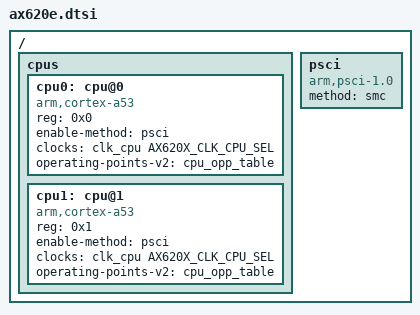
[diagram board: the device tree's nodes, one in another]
// SPDX-License-Identifier: GPL-2.0-or-later
/* AX630C AArch64 firmware uses PSCI. */
#include "../../../../arm/boot/dts/axera/ax620e-common.dtsi"

/ {
	cpus {
		#address-cells = <1>;
		#size-cells = <0>;

		cpu0: cpu@0 {
			device_type = "cpu";
			compatible = "arm,cortex-a53";
			reg = <0x0>;
			enable-method = "psci";
			clocks = <&clk_cpu AX620X_CLK_CPU_SEL>;
			operating-points-v2 = <&cpu_opp_table>;
		};

		cpu1: cpu@1 {
			device_type = "cpu";
			compatible = "arm,cortex-a53";
			reg = <0x1>;
			enable-method = "psci";
			clocks = <&clk_cpu AX620X_CLK_CPU_SEL>;
			operating-points-v2 = <&cpu_opp_table>;
		};
	};

	psci {
		compatible = "arm,psci-1.0";
		method = "smc";
	};
};
